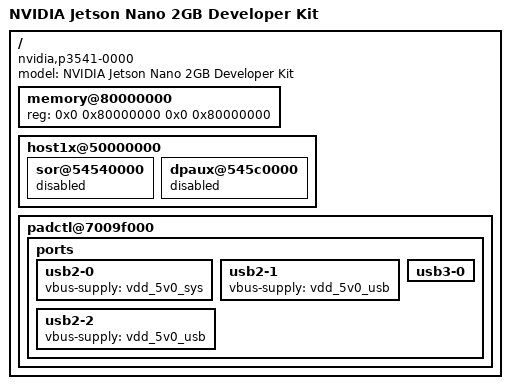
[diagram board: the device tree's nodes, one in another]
// SPDX-License-Identifier: GPL-2.0
/dts-v1/;

#include "tegra210-p3450-0000.dts"

/ {
	model = "NVIDIA Jetson Nano 2GB Developer Kit";
	compatible = "nvidia,p3541-0000", "nvidia,p3450-0000", "nvidia,tegra210";

	memory@80000000 {
		reg = <0x0 0x80000000 0x0 0x80000000>;
	};

	host1x@50000000 {
		sor@54540000 {
			status = "disabled";
		};

		dpaux@545c0000 {
			status = "disabled";
		};
	};

	padctl@7009f000 {
		ports {
			usb2-0 {
				vbus-supply = <&vdd_5v0_sys>;
			};

			usb2-1 {
				vbus-supply = <&vdd_5v0_usb>;
			};

			usb2-2 {
				vbus-supply = <&vdd_5v0_usb>;
			};

			usb3-0 {
				/delete-property/ vbus-supply;
			};
		};
	};
};
